AUTOSAR XML (schema 4-2-2)
package /Components
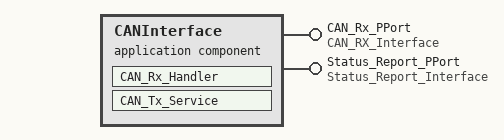
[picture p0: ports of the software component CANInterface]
  application sw component type CANInterface
    provide port CAN_Rx_PPort: provided-interface=CAN_RX_Interface
    provide port Status_Report_PPort: provided-interface=Status_Report_Interface
    provide/require port CAN_Tx_Service_PRPort: provided-required-interface=Status_Report_Interface
    behavior CANInterface_Behavior
      data receive error event CAN_Frame_Error: start-on-event=CAN_Rx_Handler
      data received event CAN_Frame_Received: start-on-event=CAN_Rx_Handler
      runnable CAN_Rx_Handler: symbol=CAN_Rx_Handler_Symbol
        data-receive-point-by-arguments:
          4 x access:
            Headlight_Command_Access: accessed-variable=CAN_Rx_PPort.Headlight_Command
            TailLight_Command_Access: accessed-variable=CAN_Rx_PPort.TailLight_Command
            TurnSignal_Command_Access: accessed-variable=CAN_Rx_PPort.TurnSignal_Command
            Brightness_Command_Access: accessed-variable=CAN_Rx_PPort.Brightness_Command
        data-send-points:
          access Status_To_CAN_Access: accessed-variable=CAN_Tx_Service_PRPort.Driver_Fault_Flag
        sync call Immediate_Send: operation=CAN_Tx_Service_PRPort.Send_CAN_Frame, timeout=50
      runnable CAN_Tx_Service: minimum-start-interval=50, symbol=CAN_Tx_Service_Symbol
        data-receive-point-by-arguments:
          access Status_Received_Access: accessed-variable=Status_Report_PPort.Driver_Fault_Flag
        data-send-points:
          access CAN_Tx_Frame_Access: accessed-variable=CAN_Tx_Service_PRPort.CAN_Frame
        sync call Send_Operation: operation=CAN_Tx_Service_PRPort.Send_CAN_Frame, timeout=50
